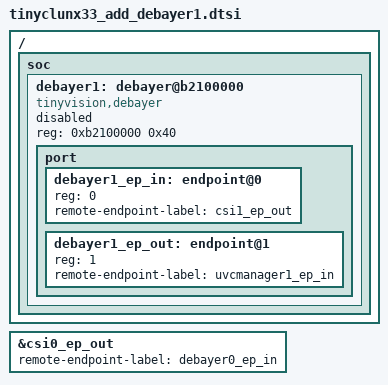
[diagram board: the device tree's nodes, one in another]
/*
 * Copyright (c) 2024-2025 tinyVision.ai Inc.
 *
 * SPDX-License-Identifier: Apache-2.0
 */

/ {
	soc {
		debayer1: debayer@b2100000 {
			compatible = "tinyvision,debayer";
			reg = <0xb2100000 0x40>;
			status = "disabled";

			port {
				#address-cells = <1>;
				#size-cells = <0>;

				debayer1_ep_in: endpoint@0 {
					reg = <0>;
					remote-endpoint-label = "csi1_ep_out";
				};

				debayer1_ep_out: endpoint@1 {
					reg = <1>;
					remote-endpoint-label = "uvcmanager1_ep_in";
				};
			};
		};
	};
};

&csi0_ep_out {
	remote-endpoint-label = "debayer0_ep_in";
};
